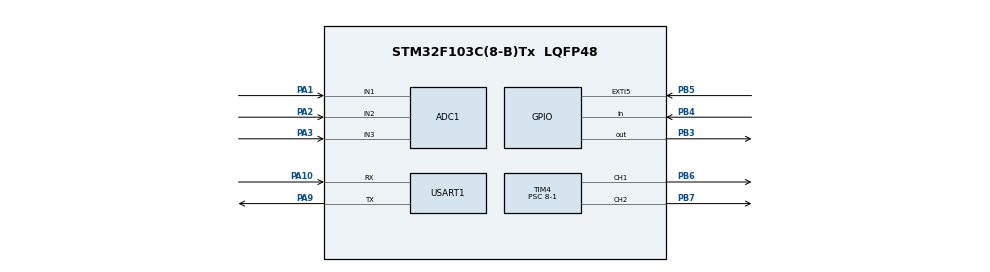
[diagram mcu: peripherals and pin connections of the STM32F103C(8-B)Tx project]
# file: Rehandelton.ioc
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ADC1.Channel-0\#ChannelRegularConversion=ADC_CHANNEL_1
ADC1.Channel-1\#ChannelRegularConversion=ADC_CHANNEL_2
ADC1.Channel-2\#ChannelRegularConversion=ADC_CHANNEL_3
ADC1.ContinuousConvMode=ENABLE
ADC1.NbrOfConversion=3
ADC1.NbrOfConversionFlag=1
ADC1.Rank-0\#ChannelRegularConversion=1
ADC1.Rank-1\#ChannelRegularConversion=2
ADC1.Rank-2\#ChannelRegularConversion=3
ADC1.SamplingTime-0\#ChannelRegularConversion=ADC_SAMPLETIME_1CYCLE_5
ADC1.SamplingTime-1\#ChannelRegularConversion=ADC_SAMPLETIME_1CYCLE_5
ADC1.SamplingTime-2\#ChannelRegularConversion=ADC_SAMPLETIME_1CYCLE_5
ADC1.master=1
Dma.ADC1.0.Direction=DMA_PERIPH_TO_MEMORY
Dma.ADC1.0.Instance=DMA1_Channel1
Dma.ADC1.0.MemDataAlignment=DMA_MDATAALIGN_WORD
Dma.ADC1.0.MemInc=DMA_MINC_ENABLE
Dma.ADC1.0.Mode=DMA_CIRCULAR
Dma.ADC1.0.PeriphDataAlignment=DMA_PDATAALIGN_WORD
Dma.ADC1.0.PeriphInc=DMA_PINC_DISABLE
Dma.ADC1.0.Priority=DMA_PRIORITY_LOW
Dma.Request0=ADC1
Mcu.Family=STM32F1
Mcu.Name=STM32F103C(8-B)Tx
Mcu.Package=LQFP48
NVIC.DMA1_Channel1_IRQn=true\:0\:0\:false\:false\:true\:false\:true\:true
NVIC.PriorityGroup=NVIC_PRIORITYGROUP_4
NVIC.TIM4_IRQn=true\:0\:0\:false\:false\:true\:true\:true\:true
PA1.Signal=ADCx_IN1
PA10.Mode=Asynchronous
PA10.Signal=USART1_RX
PA2.Signal=ADCx_IN2
PA3.Signal=ADCx_IN3
PA9.Mode=Asynchronous
PA9.Signal=USART1_TX
PB3.Signal=GPIO_Output
PB4.Signal=GPIO_Input
PB5.Signal=GPXTI5
PB6.Signal=S_TIM4_CH1
PB7.Signal=S_TIM4_CH2
PC14-OSC32_IN.Mode=LSE-External-Oscillator
PC14-OSC32_IN.Signal=RCC_OSC32_IN
PC15-OSC32_OUT.Mode=LSE-External-Oscillator
PC15-OSC32_OUT.Signal=RCC_OSC32_OUT
PD0-OSC_IN.Mode=HSE-External-Oscillator
PD0-OSC_IN.Signal=RCC_OSC_IN
PD1-OSC_OUT.Mode=HSE-External-Oscillator
PD1-OSC_OUT.Signal=RCC_OSC_OUT
ProjectManager.HeapSize=0x200
ProjectManager.StackSize=0x400
ProjectManager.TargetToolchain=STM32CubeIDE
RCC.APB1Freq_Value=8000000
RCC.APB2Freq_Value=8000000
SH.ADCx_IN1.0=ADC1_IN1,IN1
SH.ADCx_IN2.0=ADC1_IN2,IN2
SH.ADCx_IN3.0=ADC1_IN3,IN3
SH.S_TIM4_CH1.0=TIM4_CH1,PWM Generation1 CH1
SH.S_TIM4_CH2.0=TIM4_CH2,PWM Generation2 CH2
TIM4.Channel-PWM\ Generation1\ CH1=TIM_CHANNEL_1
TIM4.Channel-PWM\ Generation2\ CH2=TIM_CHANNEL_2
TIM4.Period=100-1
TIM4.Prescaler=8-1
USART1.VirtualMode=VM_ASYNC
VP_SYS_VS_ND.Mode=No_Debug
VP_TIM4_VS_ClockSourceINT.Mode=Internal
board=custom

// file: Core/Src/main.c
/* USER CODE BEGIN Header */
/**
  ******************************************************************************
  * @file           : main.c
  * @brief          : Main program body
  ******************************************************************************
  * @attention
  *
  * Copyright (c) 2022 STMicroelectronics.
  * All rights reserved.
  *
  * This software is licensed under terms that can be found in the LICENSE file
  * in the root directory of this software component.
  * If no LICENSE file comes with this software, it is provided AS-IS.
  *
  ******************************************************************************
  */
/* USER CODE END Header */
#include "main.h"

/* USER CODE BEGIN Includes */
#include "dma.h"
#include "pot.h"
#include "current_sensor.h"
#include "ntc.h"
#include "vibrator.h"
#include "drv8220.h"
/* USER CODE END Includes */

ADC_HandleTypeDef hadc1;
DMA_HandleTypeDef hdma_adc1;

TIM_HandleTypeDef htim4;

UART_HandleTypeDef huart1;

void SystemClock_Config(void);
static void MX_GPIO_Init(void);
static void MX_DMA_Init(void);
static void MX_ADC1_Init(void);
static void MX_USART1_UART_Init(void);
static void MX_TIM4_Init(void);

/* USER CODE BEGIN 0 */
//uint16_t curr_sens =0 ;
int16_t pot_sens =0;
//uint16_t ntc_sens = 0;
/* USER CODE END 0 */

int main(void)
{

  /* MCU Configuration--------------------------------------------------------*/

  /* Reset of all peripherals, Initializes the Flash interface and the Systick. */
  HAL_Init();

  /* Configure the system clock */
  SystemClock_Config();

  /* Initialize all configured peripherals */
  MX_GPIO_Init();
  MX_DMA_Init();
  MX_ADC1_Init();
  MX_USART1_UART_Init();
  MX_TIM4_Init();
  /* USER CODE BEGIN 2 */
  //HAL_GPIO_WritePin(GPIOB, GPIO_PIN_3, RESET);

// motor_config mtr_CNFG;
// mtr_CNFG.direction_set = CW_MOV;
// mtr_CNFG.out_1 = 6;
// mtr_CNFG.out_2 = 7;
 // motor_init(&mtr_CNFG, 6, 7, CW_MOV);
 // motor_start(&mtr_CNFG , CW_MOV);
  //HAL_Delay(2000);
  //motor_start(&mtr_CNFG , CCW_MOV);
  //HAL_Delay(2000);

// cs_config CS_CNFG;
// pot_config POT_CNFG;
//// ntc_config NTC_CNFG;
// vib_config VIB_CNFG;

 //dma_init();
// vib_off(&VIB_CNFG);
  /* USER CODE END 2 */

  /* Infinite loop */
  /* USER CODE BEGIN WHILE */
  while (1)
  {
//	  vib_on(&VIB_CNFG);
//	  HAL_Delay(2000);

	//  curr_sens= cs_val_get(&CS_CNFG);
	 // pot_sens= pot_val_get(&POT_CNFG);
	//  ntc_sens=  ntc_temp_get(&NTC_CNFG);
	//  motor_start(&mtr_CNFG , CW_MOV);
    /* USER CODE END WHILE */

  }
}

void SystemClock_Config(void)
{
  RCC_OscInitTypeDef RCC_OscInitStruct = {0};
  RCC_ClkInitTypeDef RCC_ClkInitStruct = {0};
  RCC_PeriphCLKInitTypeDef PeriphClkInit = {0};

  /** Initializes the RCC Oscillators according to the specified parameters
  * in the RCC_OscInitTypeDef structure.
  */
  RCC_OscInitStruct.OscillatorType = RCC_OSCILLATORTYPE_HSI;
  RCC_OscInitStruct.HSIState = RCC_HSI_ON;
  RCC_OscInitStruct.HSICalibrationValue = RCC_HSICALIBRATION_DEFAULT;
  RCC_OscInitStruct.PLL.PLLState = RCC_PLL_NONE;
  if (HAL_RCC_OscConfig(&RCC_OscInitStruct) != HAL_OK)
  {
    Error_Handler();
  }

  /** Initializes the CPU, AHB and APB buses clocks
  */
  RCC_ClkInitStruct.ClockType = RCC_CLOCKTYPE_HCLK|RCC_CLOCKTYPE_SYSCLK
                              |RCC_CLOCKTYPE_PCLK1|RCC_CLOCKTYPE_PCLK2;
  RCC_ClkInitStruct.SYSCLKSource = RCC_SYSCLKSOURCE_HSI;
  RCC_ClkInitStruct.AHBCLKDivider = RCC_SYSCLK_DIV1;
  RCC_ClkInitStruct.APB1CLKDivider = RCC_HCLK_DIV1;
  RCC_ClkInitStruct.APB2CLKDivider = RCC_HCLK_DIV1;

  if (HAL_RCC_ClockConfig(&RCC_ClkInitStruct, FLASH_LATENCY_0) != HAL_OK)
  {
    Error_Handler();
  }
  PeriphClkInit.PeriphClockSelection = RCC_PERIPHCLK_ADC;
  PeriphClkInit.AdcClockSelection = RCC_ADCPCLK2_DIV2;
  if (HAL_RCCEx_PeriphCLKConfig(&PeriphClkInit) != HAL_OK)
  {
    Error_Handler();
  }
}

static void MX_ADC1_Init(void)
{

  ADC_ChannelConfTypeDef sConfig = {0};

  /** Common config
  */
  hadc1.Instance = ADC1;
  hadc1.Init.ScanConvMode = ADC_SCAN_ENABLE;
  hadc1.Init.ContinuousConvMode = ENABLE;
  hadc1.Init.DiscontinuousConvMode = DISABLE;
  hadc1.Init.ExternalTrigConv = ADC_SOFTWARE_START;
  hadc1.Init.DataAlign = ADC_DATAALIGN_RIGHT;
  hadc1.Init.NbrOfConversion = 3;
  if (HAL_ADC_Init(&hadc1) != HAL_OK)
  {
    Error_Handler();
  }

  /** Configure Regular Channel
  */
  sConfig.Channel = ADC_CHANNEL_1;
  sConfig.Rank = ADC_REGULAR_RANK_1;
  sConfig.SamplingTime = ADC_SAMPLETIME_1CYCLE_5;
  if (HAL_ADC_ConfigChannel(&hadc1, &sConfig) != HAL_OK)
  {
    Error_Handler();
  }

  /** Configure Regular Channel
  */
  sConfig.Channel = ADC_CHANNEL_2;
  sConfig.Rank = ADC_REGULAR_RANK_2;
  if (HAL_ADC_ConfigChannel(&hadc1, &sConfig) != HAL_OK)
  {
    Error_Handler();
  }

  /** Configure Regular Channel
  */
  sConfig.Channel = ADC_CHANNEL_3;
  sConfig.Rank = ADC_REGULAR_RANK_3;
  if (HAL_ADC_ConfigChannel(&hadc1, &sConfig) != HAL_OK)
  {
    Error_Handler();
  }

}

static void MX_TIM4_Init(void)
{

  TIM_ClockConfigTypeDef sClockSourceConfig = {0};
  TIM_MasterConfigTypeDef sMasterConfig = {0};
  TIM_OC_InitTypeDef sConfigOC = {0};

  htim4.Instance = TIM4;
  htim4.Init.Prescaler = 8-1;
  htim4.Init.CounterMode = TIM_COUNTERMODE_UP;
  htim4.Init.Period = 100-1;
  htim4.Init.ClockDivision = TIM_CLOCKDIVISION_DIV1;
  htim4.Init.AutoReloadPreload = TIM_AUTORELOAD_PRELOAD_DISABLE;
  if (HAL_TIM_Base_Init(&htim4) != HAL_OK)
  {
    Error_Handler();
  }
  sClockSourceConfig.ClockSource = TIM_CLOCKSOURCE_INTERNAL;
  if (HAL_TIM_ConfigClockSource(&htim4, &sClockSourceConfig) != HAL_OK)
  {
    Error_Handler();
  }
  if (HAL_TIM_PWM_Init(&htim4) != HAL_OK)
  {
    Error_Handler();
  }
  sMasterConfig.MasterOutputTrigger = TIM_TRGO_RESET;
  sMasterConfig.MasterSlaveMode = TIM_MASTERSLAVEMODE_DISABLE;
  if (HAL_TIMEx_MasterConfigSynchronization(&htim4, &sMasterConfig) != HAL_OK)
  {
    Error_Handler();
  }
  sConfigOC.OCMode = TIM_OCMODE_PWM1;
  sConfigOC.Pulse = 0;
  sConfigOC.OCPolarity = TIM_OCPOLARITY_HIGH;
  sConfigOC.OCFastMode = TIM_OCFAST_DISABLE;
  if (HAL_TIM_PWM_ConfigChannel(&htim4, &sConfigOC, TIM_CHANNEL_1) != HAL_OK)
  {
    Error_Handler();
  }
  if (HAL_TIM_PWM_ConfigChannel(&htim4, &sConfigOC, TIM_CHANNEL_2) != HAL_OK)
  {
    Error_Handler();
  }
  HAL_TIM_MspPostInit(&htim4);

}

static void MX_USART1_UART_Init(void)
{

  huart1.Instance = USART1;
  huart1.Init.BaudRate = 115200;
  huart1.Init.WordLength = UART_WORDLENGTH_8B;
  huart1.Init.StopBits = UART_STOPBITS_1;
  huart1.Init.Parity = UART_PARITY_NONE;
  huart1.Init.Mode = UART_MODE_TX_RX;
  huart1.Init.HwFlowCtl = UART_HWCONTROL_NONE;
  huart1.Init.OverSampling = UART_OVERSAMPLING_16;
  if (HAL_UART_Init(&huart1) != HAL_OK)
  {
    Error_Handler();
  }

}

static void MX_DMA_Init(void)
{

  /* DMA controller clock enable */
  __HAL_RCC_DMA1_CLK_ENABLE();

  /* DMA interrupt init */
  /* DMA1_Channel1_IRQn interrupt configuration */
  HAL_NVIC_SetPriority(DMA1_Channel1_IRQn, 0, 0);
  HAL_NVIC_EnableIRQ(DMA1_Channel1_IRQn);

}

static void MX_GPIO_Init(void)
{
  GPIO_InitTypeDef GPIO_InitStruct = {0};

  /* GPIO Ports Clock Enable */
  __HAL_RCC_GPIOC_CLK_ENABLE();
  __HAL_RCC_GPIOD_CLK_ENABLE();
  __HAL_RCC_GPIOA_CLK_ENABLE();
  __HAL_RCC_GPIOB_CLK_ENABLE();

  /*Configure GPIO pin Output Level */
  HAL_GPIO_WritePin(GPIOB, GPIO_PIN_3, GPIO_PIN_RESET);

  /*Configure GPIO pin : PB3 */
  GPIO_InitStruct.Pin = GPIO_PIN_3;
  GPIO_InitStruct.Mode = GPIO_MODE_OUTPUT_PP;
  GPIO_InitStruct.Pull = GPIO_NOPULL;
  GPIO_InitStruct.Speed = GPIO_SPEED_FREQ_LOW;
  HAL_GPIO_Init(GPIOB, &GPIO_InitStruct);

  /*Configure GPIO pin : PB4 */
  GPIO_InitStruct.Pin = GPIO_PIN_4;
  GPIO_InitStruct.Mode = GPIO_MODE_INPUT;
  GPIO_InitStruct.Pull = GPIO_NOPULL;
  HAL_GPIO_Init(GPIOB, &GPIO_InitStruct);

  /*Configure GPIO pin : PB5 */
  GPIO_InitStruct.Pin = GPIO_PIN_5;
  GPIO_InitStruct.Mode = GPIO_MODE_IT_RISING;
  GPIO_InitStruct.Pull = GPIO_NOPULL;
  HAL_GPIO_Init(GPIOB, &GPIO_InitStruct);

}

void Error_Handler(void)
{
  __disable_irq();
  while (1)
  {
  }
}
